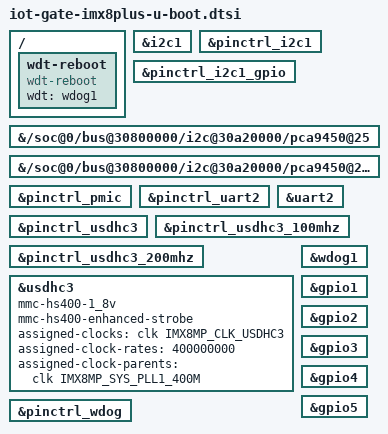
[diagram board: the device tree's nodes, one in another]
// SPDX-License-Identifier: GPL-2.0+
/*
 * Minimal U-Boot additions for CompuLab IOT-GATE-IMX8PLUS.
 * Keep SPL-visible nodes restricted to UART, PMIC/I2C and eMMC.
 */

#include "imx8mp-u-boot.dtsi"

/ {
	wdt-reboot {
		compatible = "wdt-reboot";
		wdt = <&wdog1>;
		bootph-pre-ram;
	};
};

&i2c1 {
	bootph-all;
};

&pinctrl_i2c1 {
	bootph-all;
};

&pinctrl_i2c1_gpio {
	bootph-all;
};

&{/soc@0/bus@30800000/i2c@30a20000/pca9450@25} {
	bootph-all;
};

&{/soc@0/bus@30800000/i2c@30a20000/pca9450@25/regulators} {
	bootph-all;
};

&pinctrl_pmic {
	bootph-all;
};

&pinctrl_uart2 {
	bootph-pre-ram;
};

&uart2 {
	bootph-pre-ram;
};

&pinctrl_usdhc3 {
	bootph-pre-ram;
};

&pinctrl_usdhc3_100mhz {
	bootph-pre-ram;
};

&pinctrl_usdhc3_200mhz {
	bootph-pre-ram;
};

&usdhc3 {
	bootph-pre-ram;
	mmc-hs400-1_8v;
	mmc-hs400-enhanced-strobe;
	assigned-clocks = <&clk IMX8MP_CLK_USDHC3>;
	assigned-clock-rates = <400000000>;
	assigned-clock-parents = <&clk IMX8MP_SYS_PLL1_400M>;
};

&pinctrl_wdog {
	bootph-pre-ram;
};

&wdog1 {
	bootph-pre-ram;
};

&gpio1 {
	bootph-pre-ram;
};

&gpio2 {
	bootph-pre-ram;
};

&gpio3 {
	bootph-pre-ram;
};

&gpio4 {
	bootph-pre-ram;
};

&gpio5 {
	bootph-pre-ram;
};
